# COMPUTE_CLUSTER0_CORE_CORE_MSMC_CFGS0 register map
Vendor: Texas Instruments
Peripheral module from a debugger description file (folder J721S2).
Registers are 64-bit, access per field, reset 0x0 unless marked. A register's access mark holds for its fields unless they carry their own. Offsets are as the file gives them; lines under a group give offsets from that group; [hi:lo] are bit positions; {n}, {i} and the like mark numbered series; 'fields as' and 'values as' point back to an identical list; <NAME> marks a mode.

## COMPUTE_CLUSTER0_CORE_CORE_MSMC_CFGS0
0x00 MSMC_CFGS0_pid ro reset 0x60240000
  [31:0] REVISION
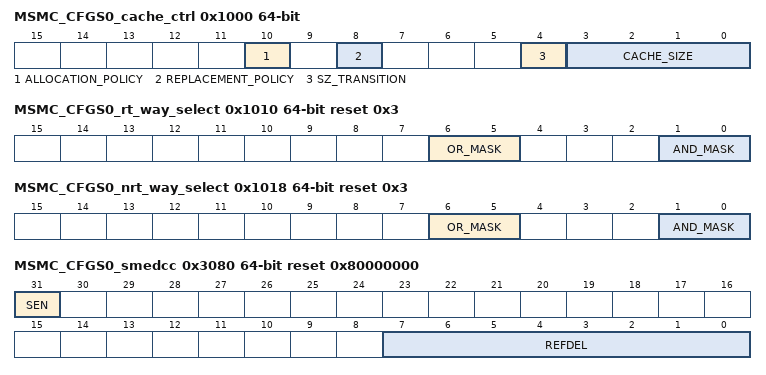
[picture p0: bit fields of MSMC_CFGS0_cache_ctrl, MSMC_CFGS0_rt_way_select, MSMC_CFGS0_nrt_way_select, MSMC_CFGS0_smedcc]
0x1000 MSMC_CFGS0_cache_ctrl
  [10] ALLOCATION_POLICY rw, [8] REPLACEMENT_POLICY rw, [4] SZ_TRANSITION ro, [3:0] CACHE_SIZE rw
0x1008 MSMC_CFGS0_cache_stat ro
0x1010 MSMC_CFGS0_rt_way_select reset 0x3
  [6:5] OR_MASK rw, [1:0] AND_MASK rw
0x1018 MSMC_CFGS0_nrt_way_select reset 0x3
  [6:5] OR_MASK rw, [1:0] AND_MASK rw
0x2048 MSMC_CFGS0_cohctrl
  [0] BCM rw
0x3080 MSMC_CFGS0_smedcc reset 0x80000000
  [31] SEN rw, [7:0] REFDEL rw
0x5000 MSMC_CFGS0_smestat ro
  [0] NULL_SLV
0x5008 MSMC_CFGS0_smirstat ro
  [0] NULL_SLV
0x5008 MSMC_CFGS0_smirws
  [0] NULL_SLV wo
0x5010 MSMC_CFGS0_smirc
  [0] NULL_SLV wo
0x5018 MSMC_CFGS0_smiestat ro
  [0] NULL_SLV
0x5018 MSMC_CFGS0_smiews
  [0] NULL_SLV wo
0x5020 MSMC_CFGS0_smiec
  [0] NULL_SLV wo
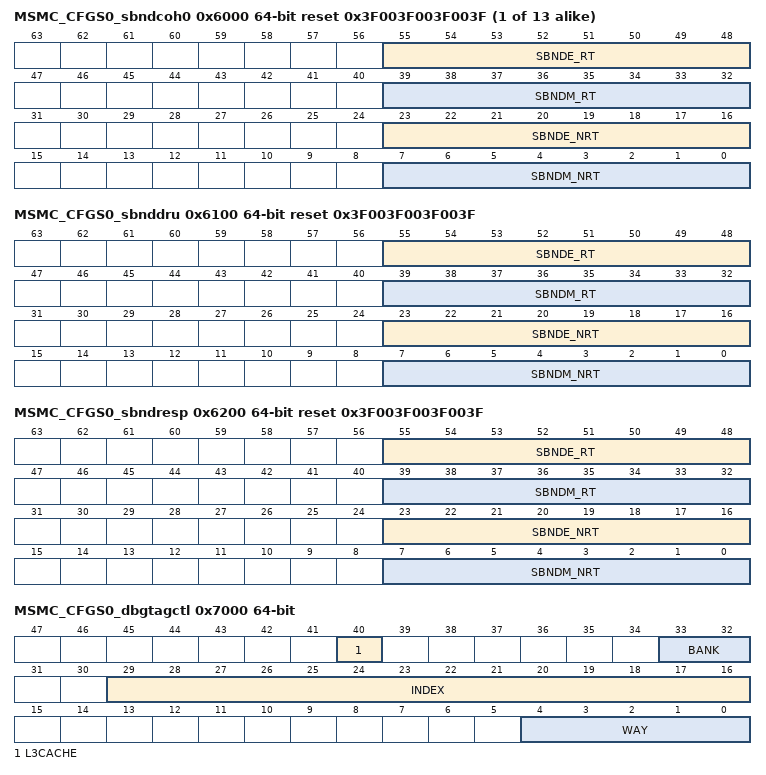
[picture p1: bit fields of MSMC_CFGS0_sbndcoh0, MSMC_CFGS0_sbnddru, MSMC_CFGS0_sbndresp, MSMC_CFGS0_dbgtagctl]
{0x6000+8i} MSMC_CFGS0_sbndcoh{i} reset 0x3F003F003F003F (i=0..12)
  [55:48] SBNDE_RT rw, [39:32] SBNDM_RT rw, [23:16] SBNDE_NRT rw, [7:0] SBNDM_NRT rw
0x6100 MSMC_CFGS0_sbnddru reset 0x3F003F003F003F
  fields as MSMC_CFGS0_sbndcoh0
0x6200 MSMC_CFGS0_sbndresp reset 0x3F003F003F003F
  fields as MSMC_CFGS0_sbndcoh0
0x7000 MSMC_CFGS0_dbgtagctl
  [40] L3CACHE rw, [33:32] BANK rw, [29:16] INDEX rw, [4:0] WAY rw
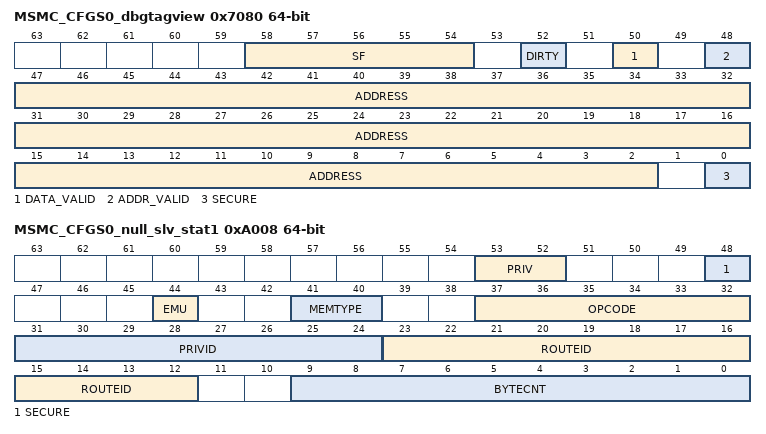
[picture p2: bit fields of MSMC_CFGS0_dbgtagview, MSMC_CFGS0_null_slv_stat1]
0x7080 MSMC_CFGS0_dbgtagview ro
  [58:54] SF, [52] DIRTY, [50] DATA_VALID, [48] ADDR_VALID, [47:2] ADDRESS, [0] SECURE
0xA000 MSMC_CFGS0_null_slv_stat0 ro
  [63:0] ADDR
0xA008 MSMC_CFGS0_null_slv_stat1 ro
  [53:52] PRIV, [48] SECURE, [44] EMU, [41:40] MEMTYPE, [37:32] OPCODE, [31:24] PRIVID, [23:12] ROUTEID, [9:0] BYTECNT
0xA018 MSMC_CFGS0_null_slv_cnt
  [7:0] COUNT rw
